VERSION ""

NS_ :

BS_:

BU_: FRANTECU ACCMP ENGINE PANEL ACECU
VAL_TABLE_ TB_COMP_STATUS 3 "Fault" 2 "Run" 1 "Stop" 0 "Standby" ;
VAL_TABLE_ TB_ACMODE 1 "AUTO" 0 "MANUAL" ;
VAL_TABLE_ TB_ON_OFF 1 "ON" 0 "OFF" ;
VAL_TABLE_ TB_OUTLET_DIR 4 "DEF" 3 "F/D" 2 "Foot" 1 "B/L" 0 "Face" ;
VAL_TABLE_ TB_INLET_DIR 1 "FRESH AIR" 0 "RECYCLING AIR" ;
VAL_TABLE_ TB_BLW_LVL 7 "HI" 6 "M5" 5 "M4" 4 "M3" 3 "M2" 2 "M1" 1 "LO" 0 "OFF" ;

BO_ 819 ACCMPMSG01: 8 ACCMP
 SG_ RCOMP : 7|16@0+ (1,0) [0|65535] "rpm"  ACECU,PANEL
 SG_ COMPSTATUS : 17|2@0+ (1,0) [0|3] ""  ACECU,PANEL

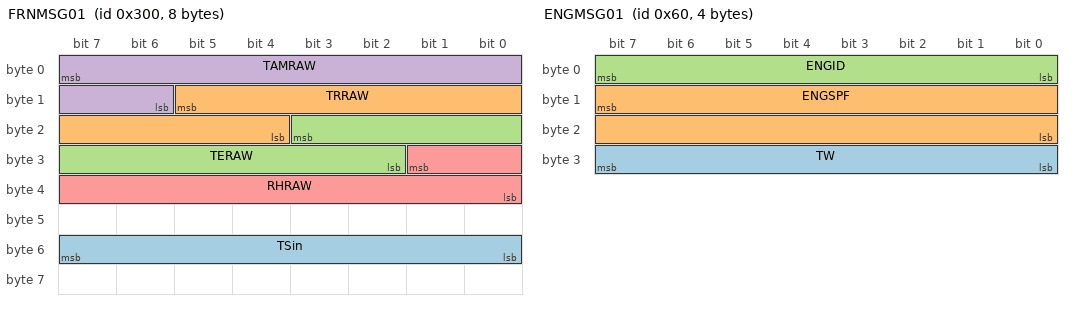
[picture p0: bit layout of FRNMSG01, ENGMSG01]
BO_ 768 FRNMSG01: 8 FRANTECU
 SG_ TSin : 55|8@0+ (17.5,0) [0|4448] "w/m^2"  ACECU,PANEL
 SG_ TRRAW : 13|10@0+ (1,0) [0|1023] ""  ACECU,PANEL
 SG_ TERAW : 19|10@0+ (1,0) [0|1023] ""  ACECU,PANEL
 SG_ TAMRAW : 7|10@0+ (1,0) [0|1023] ""  ACECU,PANEL
 SG_ RHRAW : 25|10@0+ (1,0) [0|1023] ""  ACECU,PANEL

BO_ 96 ENGMSG01: 4 ENGINE
 SG_ TW : 31|8@0+ (0.5,0) [16|127.5] "¡æ"  ACECU,PANEL
 SG_ ENGSPF : 15|16@0+ (1,0) [0|65535] "rpm"  ACECU,PANEL
 SG_ ENGID : 7|8@0+ (1,0) [0|0] ""  ACECU,PANEL

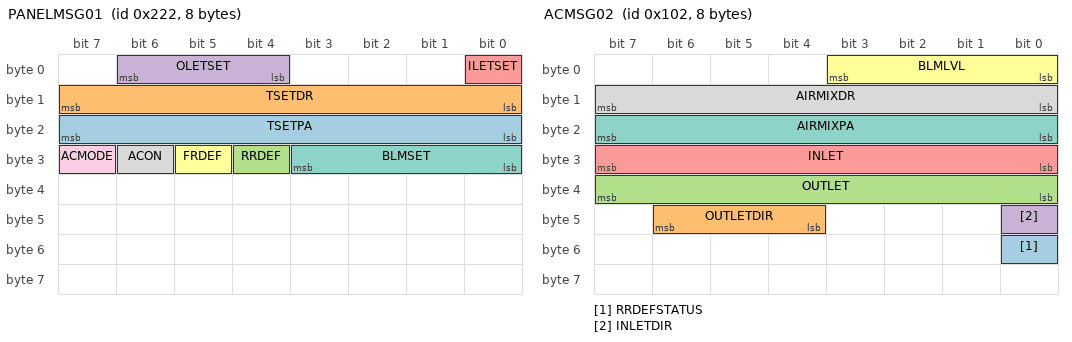
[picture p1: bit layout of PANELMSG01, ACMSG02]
BO_ 546 PANELMSG01: 8 PANEL
 SG_ TSETPA : 16|8@1+ (0.5,17.5) [17.5|32.5] "¡æ"  ACECU
 SG_ TSETDR : 8|8@1+ (0.5,17.5) [17.5|32.5] "¡æ"  ACECU
 SG_ RRDEF : 28|1@1+ (1,0) [0|1] ""  ACECU
 SG_ OLETSET : 4|3@1+ (1,0) [0|4] ""  ACECU
 SG_ ILETSET : 0|1@1+ (1,0) [0|1] ""  ACECU
 SG_ FRDEF : 29|1@1+ (1,0) [0|1] ""  ACECU
 SG_ BLMSET : 24|4@1+ (1,0) [0|7] ""  ACECU
 SG_ ACON : 30|1@1+ (1,0) [0|1] ""  ACECU
 SG_ ACMODE : 31|1@1+ (1,0) [0|1] ""  ACECU

BO_ 258 ACMSG02: 8 ACECU
 SG_ RRDEFSTATUS : 48|1@1+ (1,0) [0|1] ""  PANEL
 SG_ OUTLETDIR : 44|3@1+ (1,0) [0|4] ""  PANEL
 SG_ OUTLET : 32|8@1+ (0.5,-14) [-14|113.5] "%"  PANEL
 SG_ INLETDIR : 40|1@1+ (1,0) [0|1] ""  PANEL
 SG_ INLET : 24|8@1+ (0.5,-14) [-14|113.5] "%"  PANEL
 SG_ BLMLVL : 0|4@1+ (1,0) [0|7] ""  PANEL
 SG_ AIRMIXPA : 16|8@1+ (0.5,-14) [-14|113.5] "%"  PANEL
 SG_ AIRMIXDR : 8|8@1+ (0.5,-14) [-14|113.5] "%"  PANEL

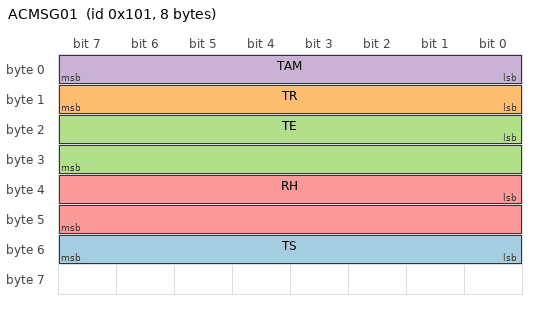
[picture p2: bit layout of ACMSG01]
BO_ 257 ACMSG01: 8 ACECU
 SG_ TS : 48|8@1+ (17.5,0) [0|4448] "w/m^2"  PANEL
 SG_ TR : 8|8@1+ (0.25,-6.5) [-6.5|57.25] "¡æ"  PANEL
 SG_ TE : 16|16@1+ (0.1,-30) [-30|60] "¡æ"  PANEL
 SG_ TAM : 0|8@1+ (0.32,-30.8) [-30.8|50.8] "¡æ"  PANEL
 SG_ RH : 32|16@1+ (0.16,10) [10|90] "%"  PANEL

BA_DEF_  "BusType" STRING ;
BA_DEF_  "GenNWMApBusSleep" STRING ;
BA_DEF_  "GenNWMApCanNormal" STRING ;
BA_DEF_  "GenNWMApCanOff" STRING ;
BA_DEF_  "GenNWMApCanOn" STRING ;
BA_DEF_  "GenNWMApCanSleep" STRING ;
BA_DEF_  "GenNWMApCanWakeUp" STRING ;
BA_DEF_  "GenNWMGotoMode_Awake" STRING ;
BA_DEF_  "GenNWMGotoMode_BusSleep" STRING ;
BA_DEF_  "GenNWMTalkNM" STRING ;
BA_DEF_ BO_  "GenMsgCycleTime" INT 2 50000;
BA_DEF_ BO_  "GenMsgDelayTime" INT 1 1000;
BA_DEF_ BO_  "GenMsgNrOfRepetitions" INT 1 999999;
BA_DEF_ SG_  "GenSigStartValue" FLOAT 0 100000000000;
BA_DEF_  "GenEnvVarEndingDsp" STRING ;
BA_DEF_  "GenEnvVarEndingSnd" STRING ;
BA_DEF_  "GenEnvVarPrefix" STRING ;
BA_DEF_ SG_  "GenSigEnvVarType" ENUM  "int","float","undef";
BA_DEF_DEF_  "BusType" "CAN";
BA_DEF_DEF_  "GenNWMApBusSleep" "apBusSleep()";
BA_DEF_DEF_  "GenNWMApCanNormal" "apCanNormal()";
BA_DEF_DEF_  "GenNWMApCanOff" "apCanOff()";
BA_DEF_DEF_  "GenNWMApCanOn" "apCanOn()";
BA_DEF_DEF_  "GenNWMApCanSleep" "apCanSleep()";
BA_DEF_DEF_  "GenNWMApCanWakeUp" "apCanWakeUp()";
BA_DEF_DEF_  "GenNWMGotoMode_Awake" "GotoMode_Awake()";
BA_DEF_DEF_  "GenNWMGotoMode_BusSleep" "GotoMode_BusSleep()";
BA_DEF_DEF_  "GenNWMTalkNM" "TalkNM()";
BA_DEF_DEF_  "GenMsgCycleTime" 100;
BA_DEF_DEF_  "GenMsgDelayTime" 1;
BA_DEF_DEF_  "GenMsgNrOfRepetitions" 1;
BA_DEF_DEF_  "GenSigStartValue" 0;
BA_DEF_DEF_  "GenEnvVarEndingDsp" "Dsp_";
BA_DEF_DEF_  "GenEnvVarEndingSnd" "_";
BA_DEF_DEF_  "GenEnvVarPrefix" "Env";
BA_DEF_DEF_  "GenSigEnvVarType" "undef";
BA_ "GenMsgCycleTime" BO_ 96 50;
BA_ "GenMsgCycleTime" BO_ 258 250;
BA_ "GenMsgCycleTime" BO_ 257 250;
BA_ "GenSigStartValue" SG_ 96 TW 32;
BA_ "GenSigStartValue" SG_ 96 ENGID 170;
BA_ "GenSigStartValue" SG_ 546 TSETPA 15;
BA_ "GenSigStartValue" SG_ 546 TSETDR 15;
BA_ "GenSigStartValue" SG_ 258 OUTLET 28;
BA_ "GenSigStartValue" SG_ 258 INLET 28;
BA_ "GenSigStartValue" SG_ 258 AIRMIXPA 28;
BA_ "GenSigStartValue" SG_ 258 AIRMIXDR 28;
BA_ "GenSigStartValue" SG_ 257 TR 26;
BA_ "GenSigStartValue" SG_ 257 TE 300;
BA_ "GenSigStartValue" SG_ 257 TAM 96.25;
VAL_ 819 COMPSTATUS 3 "Fault" 2 "Run" 1 "Stop" 0 "Standby" ;
VAL_ 546 RRDEF 1 "ON" 0 "OFF" ;
VAL_ 546 OLETSET 4 "DEF" 3 "F/D" 2 "Foot" 1 "B/L" 0 "Face" ;
VAL_ 546 ILETSET 1 "FRESH AIR" 0 "RECYCLING AIR" ;
VAL_ 546 FRDEF 1 "ON" 0 "OFF" ;
VAL_ 546 BLMSET 7 "HI" 6 "M5" 5 "M4" 4 "M3" 3 "M2" 2 "M1" 1 "LO" 0 "OFF" ;
VAL_ 546 ACON 1 "ON" 0 "OFF" ;
VAL_ 546 ACMODE 1 "AUTO" 0 "MANUAL" ;
VAL_ 258 RRDEFSTATUS 1 "ON" 0 "OFF" ;
VAL_ 258 OUTLETDIR 4 "DEF" 3 "F/D" 2 "Foot" 1 "B/L" 0 "Face" ;
VAL_ 258 INLETDIR 1 "FRESH AIR" 0 "RECYCLING AIR" ;
VAL_ 258 BLMLVL 7 "HI" 6 "M5" 5 "M4" 4 "M3" 3 "M2" 2 "M1" 1 "LO" 0 "OFF" ;
